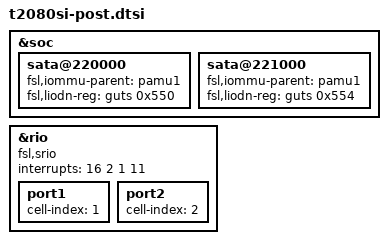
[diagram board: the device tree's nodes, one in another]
/include/ "t2081si-post.dtsi"
&soc {
/include/ "qoriq-sata2-0.dtsi"
	sata@220000 {
		fsl,iommu-parent = <&pamu1>;
		fsl,liodn-reg = <&guts 0x550>;  
	};
/include/ "qoriq-sata2-1.dtsi"
	sata@221000 {
		fsl,iommu-parent = <&pamu1>;
		fsl,liodn-reg = <&guts 0x554>;  
	};
};
&rio {
	compatible = "fsl,srio";
	interrupts = <16 2 1 11>;
	#address-cells = <2>;
	#size-cells = <2>;
	ranges;
	port1 {
		#address-cells = <2>;
		#size-cells = <2>;
		cell-index = <1>;
	};
	port2 {
		#address-cells = <2>;
		#size-cells = <2>;
		cell-index = <2>;
	};
};
